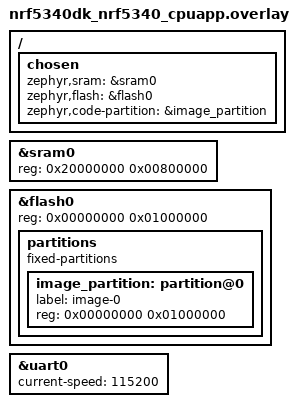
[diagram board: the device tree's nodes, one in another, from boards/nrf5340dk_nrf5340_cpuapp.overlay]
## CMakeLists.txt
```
#
# Copyright (c) 2021 Nordic Semiconductor
#
# SPDX-License-Identifier: LicenseRef-Nordic-5-Clause
#
cmake_minimum_required(VERSION 3.20)

find_package(Zephyr REQUIRED HINTS $ENV{ZEPHYR_BASE})
project(edge_ib C CXX)

# ---------------------------------------------------------
# 1. APPLICATION SOURCES
# ---------------------------------------------------------
target_sources(app PRIVATE
  src/main.cpp
  src/ML_Models/model_data.cc
  src/inference.cpp
  src/profiling.cpp
)

zephyr_library_include_directories(${CMAKE_CURRENT_SOURCE_DIR})
```

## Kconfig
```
# Options of this app. Set values in prj.conf, in a snippet or with -D<OPTION>=... at build time.

menu "Edge inference benchmark app"

config APP_TENSOR_ARENA_SIZE
	int "TFLM tensor arena size (bytes)"
	default 131072
	help
	  Static memory for all tensors of the inference (placed in RAM/.bss).
	  Default 128 KiB: fits the real nRF5340 DK (448 KiB RAM for the app).
	  The Renode variant sets more to test models of any size.
	  Actual need: see "Total Arena: used / size" in the UART log.

endmenu

# Must stay at the end: loads all Zephyr options (otherwise Kconfig only knows ours)
source "Kconfig.zephyr"
```

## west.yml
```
# West manifest for the nRF5340 firmware.
# Pins the SDK version and adds modules that NCS does not fetch by default.
#
#   west init -l <this directory>   &&   west update

manifest:
  version: "0.13"

  remotes:
    - name: ncs
      url-base: https://github.com/nrfconnect
    - name: zephyrproject
      url-base: https://github.com/zephyrproject-rtos

  projects:
    # nRF Connect SDK; import: true pulls in zephyr + all NCS modules
    - name: nrf
      remote: ncs
      repo-path: sdk-nrf
      revision: v2.6.0
      import: true

    # TFLite Micro is in Zephyr's "optional" submanifest, which NCS does not
    # import. Revision and path = as in Zephyr's optional.yaml for NCS v2.6.0
    # (the path ends up in __FILE__ strings, so it changes the binary).
    - name: tflite-micro
      remote: zephyrproject
      revision: 1a34dcab41e7e0e667db72d6a40999c1ec9c510c
      path: optional/modules/lib/tflite-micro
```

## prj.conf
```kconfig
#
# Copyright (c) 2021 Nordic Semiconductor ASA
#
# SPDX-License-Identifier: LicenseRef-Nordic-5-Clause
#

# Configuration shared by both variants (#1 Renode, #2 DK).
# Variant-specific settings live in snippets/<variant>/.

# Optimize for speed (we measure latency); size optimization would save flash instead
# CONFIG_SIZE_OPTIMIZATIONS=y
CONFIG_SPEED_OPTIMIZATIONS=y

# --- TensorFlow Lite Micro (C++17) with CMSIS-NN kernels ---
CONFIG_MAIN_STACK_SIZE=16384
CONFIG_CPP=y
CONFIG_NEWLIB_LIBC=y
CONFIG_LIB_CPLUSPLUS=y
CONFIG_STD_CPP17=y
CONFIG_TENSORFLOW_LITE_MICRO=y
CONFIG_TENSORFLOW_LITE_MICRO_CMSIS_NN_KERNELS=y

# --- Console output over UART (printk, floats for the RESULT line) ---
CONFIG_UART_CONSOLE=y
CONFIG_CONSOLE=y
CONFIG_SERIAL=y
CONFIG_LOG=y
CONFIG_PRINTK=y

CONFIG_CBPRINTF_FP_SUPPORT=y

# Synchronous logging/printk: no lost output when a lot is printed at once
CONFIG_LOG_MODE_IMMEDIATE=y
CONFIG_PRINTK_SYNC=y
CONFIG_LOG_BUFFER_SIZE=8192
```

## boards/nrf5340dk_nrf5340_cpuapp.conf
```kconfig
#
# Copyright (c) 2022 Nordic Semiconductor
#
# SPDX-License-Identifier: LicenseRef-Nordic-5-Clause
#

# Distance Measurement
CONFIG_DM_MODULE_RPC=y
CONFIG_DM_MODULE_RPC_CLIENT=y

CONFIG_TEST_RANDOM_GENERATOR=y
# CONFIG_ENTROPY_GENERATOR=y
# CONFIG_ENTROPY_DEVICE_RANDOM_GENERATOR=y
CONFIG_MPSL=n

# NRF RPC
CONFIG_NRF_RPC_THREAD_POOL_SIZE=2

# SYSTEM WORKQUEUE
CONFIG_SYSTEM_WORKQUEUE_STACK_SIZE=3072
```

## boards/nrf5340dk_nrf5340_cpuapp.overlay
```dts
// /*
//  * Copyright (c) 2022 Nordic Semiconductor ASA
//  *
//  * SPDX-License-Identifier: LicenseRef-Nordic-5-Clause
//  */

// #include <zephyr/dt-bindings/ipc_service/static_vrings.h>

// / {
// 	chosen {
// 		/delete-property/ zephyr,ipc_shm;
// 	};

// 	reserved-memory {
// 		/delete-node/ memory@20070000;

// 		sram_ipc0: memory@20070000 {
// 			reg = <0x20070000 0x8000>;
// 		};

// 		sram_ipc1: memory@20078000 {
// 			reg = <0x20078000 0x8000>;
// 		};
// 	};

// 	ipc {
// 		/delete-node/ ipc0;

// 		ipc0: ipc0 {
// 			compatible = "zephyr,ipc-openamp-static-vrings";
// 			memory-region = <&sram_ipc0>;
// 			mboxes = <&mbox 0>, <&mbox 1>;
// 			mbox-names = "tx", "rx";
// 			role = "host";
// 			status = "okay";
// 		};

// 		ipc1: ipc1 {
// 			compatible = "zephyr,ipc-openamp-static-vrings";
// 			memory-region = <&sram_ipc1>;
// 			mboxes = <&mbox 2>, <&mbox 3>;
// 			mbox-names = "tx", "rx";
// 			role = "host";
// 			zephyr,buffer-size = <2048>;
// 			status = "okay";
// 		};
// 	};
// };

//  /* Enable pin forwarding to network core. The selected pins will be used by
//   * Distance Measurement module for debug purposes.
//   *
//   * Note: Pay attention to assign the same GPIO pins as those provide in network core DTS overlay.
//   */
// &gpio_fwd {
// 	compatible = "nordic,nrf-gpio-forwarder";
// 	dm-gpio-if {
// 		gpios = <&gpio0 26 0>,
// 			<&gpio0 27 0>;
// 		};
// };

// &uart0 {
//     current-speed = <230400>;
//     status = "okay";
// };


/* boards/nrf5340dk_nrf5340_cpuapp.overlay */

/ {
	chosen {
		zephyr,sram = &sram0;
		zephyr,flash = &flash0;
		zephyr,code-partition = &image_partition;
	};
};

/* 1. RAM auf 8 MB erweitern */
&sram0 {
	reg = <0x20000000 0x00800000>; /* 8 MB virtueller SRAM */
};

/* 2. Flash auf 16 MB erweitern und Partitionierung anpassen */
&flash0 {
	reg = <0x00000000 0x01000000>; /* 16 MB virtueller Flash */

	partitions {
		compatible = "fixed-partitions";
		#address-cells = <1>;
		#size-cells = <1>;

		/* Voller Bereich als Binary-Image */
		image_partition: partition@0 {
			label = "image-0";
			reg = <0x00000000 0x01000000>;
		};
	};
};

/* UART für Ausgaben aktiv halten */
&uart0 {
	status = "okay";
	current-speed = <115200>;
};
```

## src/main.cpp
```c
#include <zephyr/kernel.h>
#include <zephyr/sys/printk.h>
#include "inference.hpp"
#include "data.hpp"
#include "ML_Models/model_data.h"

int main(void)
{
    printk("Starting Edge AI Benchmark on nRF5340...\n");

    if (!inference_init(g_model_data)) {
        printk("Initialization aborted.\n");
        return -1;
    }

    InferenceResult res;

    // First run (also records the per-layer profile)
    if (!inference_run(TEST_INPUT_SAMPLES[0], &res)) {
        printk("Inference failed.\n");
        return -1;
    }
    printk("[Warm-up Run] Pred: %6.3f | Latency: %u us | Cycles: %u\n",
           (double)res.prediction,
           res.execution_time_us,
           res.execution_cycles);

    // Print the detailed per-layer report
    inference_dump_profiling();

    // Machine-readable (JSON) for scripts/run_json.py, always the last line.
    // sha256 of the .tflite (embedded by codegen) -> the measurement is linked to the right model.
    printk("RESULT {\"model_sha256\": \"%s\", \"cycles\": %u, \"latency_us\": %u, "
           "\"arena_used_bytes\": %u, \"prediction\": %.4f}\n",
           g_model_data_sha256,
           res.execution_cycles,
           res.execution_time_us,
           static_cast<unsigned int>(inference_arena_used()),
           (double)res.prediction);

    return 0;
}
```

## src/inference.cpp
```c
#include "inference.hpp"
#include "profiling.hpp"

#include <zephyr/kernel.h>
#include <zephyr/sys/printk.h>
#include <string.h>
#include <math.h>

#include "tensorflow/lite/micro/recording_micro_interpreter.h"
#include "tensorflow/lite/micro/micro_mutable_op_resolver.h"
#include "tensorflow/lite/micro/system_setup.h"
#include "tensorflow/lite/schema/schema_generated.h"

// Size comes from Kconfig (CONFIG_APP_TENSOR_ARENA_SIZE) and differs per variant
#define TENSOR_ARENA_SIZE CONFIG_APP_TENSOR_ARENA_SIZE

alignas(16) static uint8_t tensor_arena[TENSOR_ARENA_SIZE];

static tflite::RecordingMicroInterpreter* interpreter = nullptr;
static const tflite::Model* current_model = nullptr;
static TfLiteTensor* input_tensor = nullptr;
static TfLiteTensor* output_tensor = nullptr;
static bool is_initialized = false;
static int total_input_elements = 0;

static DwtMicroProfiler profiler;

bool inference_init(const unsigned char* model_data)
{
    if (model_data == nullptr) {
        printk("Error: Model pointer is NULL\n");
        return false;
    }

    CoreDebug->DEMCR |= CoreDebug_DEMCR_TRCENA_Msk;
    DWT->CTRL |= DWT_CTRL_CYCCNTENA_Msk;
    DWT->CYCCNT = 0;

    tflite::InitializeTarget();

    current_model = tflite::GetModel(model_data);
    if (current_model->version() != TFLITE_SCHEMA_VERSION) {
        printk("Error: Model schema mismatch (Expected %d, got %d)\n",
               TFLITE_SCHEMA_VERSION, current_model->version());
        return false;
    }

    static tflite::MicroMutableOpResolver<30> resolver;
    resolver.AddFullyConnected();
    resolver.AddConv2D();
    resolver.AddDepthwiseConv2D();
    resolver.AddAveragePool2D();
    resolver.AddMaxPool2D();
    resolver.AddRelu();
    resolver.AddRelu6();
    resolver.AddHardSwish();
    resolver.AddSum();
    resolver.AddMean();
    resolver.AddAdd();
    resolver.AddMul();
    resolver.AddSub();
    resolver.AddLogistic();
    resolver.AddReshape();
    resolver.AddPad();
    resolver.AddQuantize();
    resolver.AddDequantize();
    resolver.AddSoftmax();

    static tflite::RecordingMicroInterpreter static_interpreter(
        current_model,
        resolver,
        tensor_arena,
        TENSOR_ARENA_SIZE,
        nullptr,
        &profiler
    );

    interpreter = &static_interpreter;

    if (interpreter->AllocateTensors() != kTfLiteOk) {
        printk("Error: AllocateTensors failed\n");
        return false;
    }

    input_tensor  = interpreter->input(0);
    output_tensor = interpreter->output(0);

    total_input_elements = 1;
    for (int i = 0; i < input_tensor->dims->size; ++i) {
        total_input_elements *= input_tensor->dims->data[i];
    }

    is_initialized = true;

    printk("TFLM initialized. Inputs: %d | Total Arena: %u / %d bytes\n",
           total_input_elements,
           static_cast<unsigned int>(interpreter->arena_used_bytes()), 
           TENSOR_ARENA_SIZE);

    printk("\n============================ MEMORY PROFILING REPORT ============================\n");
    interpreter->GetMicroAllocator().PrintAllocations();
    printk("==================================================================================\n\n");

    return true;
}

size_t inference_arena_used(void)
{
    return is_initialized ? interpreter->arena_used_bytes() : 0;
}

bool inference_run(const float* raw_features, InferenceResult* result)
{
    if (!is_initialized || raw_features == nullptr || result == nullptr) {
        return false;
    }

    if (input_tensor->type == kTfLiteFloat32) {
        memcpy(input_tensor->data.f, raw_features, sizeof(float) * total_input_elements);
    } 
    else if (input_tensor->type == kTfLiteInt8) {
        const float scale = input_tensor->params.scale;
        const int32_t zero_point = input_tensor->params.zero_point;

        for (int i = 0; i < total_input_elements; ++i) {
            int32_t q = static_cast<int32_t>(roundf(raw_features[i] / scale)) + zero_point;
            if (q < -128) q = -128;
            if (q > 127)  q = 127;
            input_tensor->data.int8[i] = static_cast<int8_t>(q);
        }
    } else {
        return false;
    }

    profiler.Reset();

    uint32_t start_cycles = DWT->CYCCNT;
    TfLiteStatus status = interpreter->Invoke();
    uint32_t stop_cycles = DWT->CYCCNT;
    uint32_t delta_cycles = stop_cycles - start_cycles;

    if (status != kTfLiteOk) {
        return false;
    }

    float predicted_value = 0.0f;
    if (output_tensor->type == kTfLiteFloat32) {
        predicted_value = output_tensor->data.f[0];
    } else if (output_tensor->type == kTfLiteInt8) {
        const float scale = output_tensor->params.scale;
        const int32_t zero_point = output_tensor->params.zero_point;
        predicted_value = (static_cast<float>(output_tensor->data.int8[0]) - zero_point) * scale;
    }

    result->prediction = predicted_value;
    result->execution_cycles = delta_cycles;
    result->execution_time_us = delta_cycles / 128;

    return true;
}

void inference_dump_profiling(void)
{
    if (current_model && interpreter) {
        profiler.PrintSummary(current_model, 128);

        printk("\n============================ MEMORY PROFILING REPORT ============================\n");
        interpreter->GetMicroAllocator().PrintAllocations();
        printk("==================================================================================\n\n");
    }
}
```

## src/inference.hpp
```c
#pragma once

#include <stddef.h>
#include <stdint.h>
#include <stdbool.h>

#ifdef __cplusplus
extern "C" {
#endif

typedef struct {
    float prediction;
    uint32_t execution_cycles;
    uint32_t execution_time_us;
} InferenceResult;

bool inference_init(const unsigned char* model_data);
bool inference_run(const float* raw_features, InferenceResult* result);
void inference_dump_profiling(void);
size_t inference_arena_used(void);

#ifdef __cplusplus
}
#endif
```

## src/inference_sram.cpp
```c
#include "inference.hpp"
#include "profiling.hpp"

#include <zephyr/kernel.h>
#include <zephyr/sys/printk.h>
#include <string.h>
#include <math.h>

#include "tensorflow/lite/micro/recording_micro_interpreter.h"
#include "tensorflow/lite/micro/micro_mutable_op_resolver.h"
#include "tensorflow/lite/micro/system_setup.h"
#include "tensorflow/lite/schema/schema_generated.h"

// 2 MB buffer for the MobileNet flatbuffer mirrored into SRAM
#define MODEL_SRAM_BUFFER_SIZE (3 * 1024 * 1024)
alignas(16) static uint8_t s_model_sram[MODEL_SRAM_BUFFER_SIZE];

// 3 MB tensor arena for activations, intermediate tensors and scratch buffers
// Size comes from Kconfig (CONFIG_APP_TENSOR_ARENA_SIZE) and differs per variant
#define TENSOR_ARENA_SIZE CONFIG_APP_TENSOR_ARENA_SIZE
alignas(16) static uint8_t tensor_arena[TENSOR_ARENA_SIZE];

static tflite::RecordingMicroInterpreter* interpreter = nullptr;
static const tflite::Model* current_model = nullptr;
static TfLiteTensor* input_tensor = nullptr;
static TfLiteTensor* output_tensor = nullptr;
static bool is_initialized = false;
static int total_input_elements = 0;

static DwtMicroProfiler profiler;

// Size of the generated model from model_data.h/cc
extern const size_t g_model_data_len;

bool inference_init(const unsigned char* model_data)
{
    if (model_data == nullptr) {
        printk("Error: Model pointer is NULL\n");
        return false;
    }

    // Enable the DWT cycle counter
    CoreDebug->DEMCR |= CoreDebug_DEMCR_TRCENA_Msk;
    DWT->CTRL |= DWT_CTRL_CYCCNTENA_Msk;
    DWT->CYCCNT = 0;

    tflite::InitializeTarget();

    // 1. Check the model size and mirror the whole model into SRAM
    if (g_model_data_len > MODEL_SRAM_BUFFER_SIZE) {
        printk("Error: Model size (%u bytes) exceeds SRAM buffer (%u bytes)!\n",
               (unsigned int)g_model_data_len, MODEL_SRAM_BUFFER_SIZE);
        return false;
    }

    memcpy(s_model_sram, model_data, g_model_data_len);

    printk("[SRAM Mirror] Model mirrored to SRAM at: 0x%08X (%u bytes)\n",
           (uintptr_t)s_model_sram, (unsigned int)g_model_data_len);

    // 2. GetModel uses the SRAM buffer directly (weights are now read from SRAM)
    current_model = tflite::GetModel(s_model_sram);
    if (current_model->version() != TFLITE_SCHEMA_VERSION) {
        printk("Error: Model schema mismatch (Expected %d, got %d)\n",
               TFLITE_SCHEMA_VERSION, current_model->version());
        return false;
    }

    // 3. Op resolver with room for 30 ops
    static tflite::MicroMutableOpResolver<30> resolver;
    resolver.AddFullyConnected();
    resolver.AddConv2D();
    resolver.AddDepthwiseConv2D();
    resolver.AddAveragePool2D();
    resolver.AddMaxPool2D();
    resolver.AddRelu();
    resolver.AddRelu6();
    resolver.AddHardSwish();
    resolver.AddSum();
    resolver.AddMean();
    resolver.AddAdd();
    resolver.AddMul();
    resolver.AddSub();
    resolver.AddLogistic();
    resolver.AddReshape();
    resolver.AddPad();
    resolver.AddTranspose();
    resolver.AddQuantize();
    resolver.AddDequantize();
    resolver.AddSoftmax();

    static tflite::RecordingMicroInterpreter static_interpreter(
        current_model,
        resolver,
        tensor_arena,
        TENSOR_ARENA_SIZE,
        nullptr,
        &profiler
    );

    interpreter = &static_interpreter;

    if (interpreter->AllocateTensors() != kTfLiteOk) {
        printk("Error: AllocateTensors failed\n");
        return false;
    }

    input_tensor  = interpreter->input(0);
    output_tensor = interpreter->output(0);

    total_input_elements = 1;
    for (int i = 0; i < input_tensor->dims->size; ++i) {
        total_input_elements *= input_tensor->dims->data[i];
    }

    is_initialized = true;

    printk("TFLM initialized. Inputs: %d | Total Arena: %u / %d bytes\n",
           total_input_elements,
           static_cast<unsigned int>(interpreter->arena_used_bytes()), 
           TENSOR_ARENA_SIZE);

    printk("\n============================ MEMORY PROFILING REPORT ============================\n");
    interpreter->GetMicroAllocator().PrintAllocations();
    printk("==================================================================================\n\n");

    return true;
}

bool inference_run(const float* raw_features, InferenceResult* result)
{
    if (!is_initialized || raw_features == nullptr || result == nullptr) {
        return false;
    }

    if (input_tensor->type == kTfLiteFloat32) {
        memcpy(input_tensor->data.f, raw_features, sizeof(float) * total_input_elements);
    } 
    else if (input_tensor->type == kTfLiteInt8) {
        const float scale = input_tensor->params.scale;
        const int32_t zero_point = input_tensor->params.zero_point;

        for (int i = 0; i < total_input_elements; ++i) {
            int32_t q = static_cast<int32_t>(roundf(raw_features[i] / scale)) + zero_point;
            if (q < -128) q = -128;
            if (q > 127)  q = 127;
            input_tensor->data.int8[i] = static_cast<int8_t>(q);
        }
    } else {
        return false;
    }

    profiler.Reset();

    uint32_t start_cycles = DWT->CYCCNT;
    TfLiteStatus status = interpreter->Invoke();
    uint32_t stop_cycles = DWT->CYCCNT;
    uint32_t delta_cycles = stop_cycles - start_cycles;

    if (status != kTfLiteOk) {
        return false;
    }

    float predicted_value = 0.0f;
    if (output_tensor->type == kTfLiteFloat32) {
        predicted_value = output_tensor->data.f[0];
    } else if (output_tensor->type == kTfLiteInt8) {
        const float scale = output_tensor->params.scale;
        const int32_t zero_point = output_tensor->params.zero_point;
        predicted_value = (static_cast<float>(output_tensor->data.int8[0]) - zero_point) * scale;
    }

    result->prediction = predicted_value;
    result->execution_cycles = delta_cycles;
    result->execution_time_us = delta_cycles / 128;

    return true;
}

void inference_dump_profiling(void)
{
    if (current_model && interpreter) {
        profiler.PrintSummary(current_model, 128);

        printk("\n============================ MEMORY PROFILING REPORT ============================\n");
        interpreter->GetMicroAllocator().PrintAllocations();
        printk("==================================================================================\n\n");
    }
}
```

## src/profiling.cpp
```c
#include "profiling.hpp"
#include <zephyr/sys/printk.h>
#include <zephyr/kernel.h>
#include <string.h>

DwtMicroProfiler::DwtMicroProfiler() : num_events_(0) {
    memset(events_, 0, sizeof(events_));
}

void DwtMicroProfiler::InitHardware() {
    CoreDebug->DEMCR |= CoreDebug_DEMCR_TRCENA_Msk;

    uint32_t ctrl_mask = DWT_CTRL_CYCCNTENA_Msk;
#if defined(DWT_CTRL_LSUEVTENA_Msk)
    ctrl_mask |= DWT_CTRL_LSUEVTENA_Msk;
#elif defined(DWT_CTRL_LSUCNTENA_Msk)
    ctrl_mask |= DWT_CTRL_LSUCNTENA_Msk;
#endif

#if defined(DWT_CTRL_CPIEVTENA_Msk)
    ctrl_mask |= DWT_CTRL_CPIEVTENA_Msk;
#elif defined(DWT_CTRL_CPICNTENA_Msk)
    ctrl_mask |= DWT_CTRL_CPICNTENA_Msk;
#endif

    DWT->CTRL |= ctrl_mask;
    DWT->CYCCNT = 0;
    DWT->LSUCNT = 0;
    DWT->CPICNT = 0;

    printk("[Profiler] Cortex-M33 DWT Memory & Stall Profiler: ACTIVE\n");
}

void DwtMicroProfiler::Reset() {
    num_events_ = 0;
    DWT->LSUCNT = 0;
    DWT->CPICNT = 0;
}

uint32_t DwtMicroProfiler::BeginEvent(const char* tag) {
    if (num_events_ >= PROFILER_MAX_EVENTS) {
        return 0xFFFFFFFF;
    }
    uint32_t handle = num_events_++;
    events_[handle].tag = tag;
    events_[handle].start_lsu    = DWT->LSUCNT;
    events_[handle].start_cpi    = DWT->CPICNT;
    events_[handle].start_cycles = DWT->CYCCNT;
    return handle;
}

void DwtMicroProfiler::EndEvent(uint32_t event_handle) {
    uint32_t stop_cycles = DWT->CYCCNT;
    uint32_t stop_lsu    = DWT->LSUCNT;
    uint32_t stop_cpi    = DWT->CPICNT;

    if (event_handle != 0xFFFFFFFF && event_handle < num_events_) {
        events_[event_handle].total_cycles = stop_cycles - events_[event_handle].start_cycles;
        events_[event_handle].total_lsu    = (stop_lsu - events_[event_handle].start_lsu) & 0xFF;
        events_[event_handle].total_cpi    = (stop_cpi - events_[event_handle].start_cpi) & 0xFF;
    }
}

uint64_t DwtMicroProfiler::CalculateOperatorMacs(const tflite::Operator* op, 
                                               const tflite::SubGraph* subgraph, 
                                               tflite::BuiltinOperator op_type) {
    if (!op || !subgraph) return 0;

    auto inputs  = op->inputs();
    auto outputs = op->outputs();
    auto tensors = subgraph->tensors();

    if (!inputs || !outputs || !tensors) return 0;
    if (inputs->size() < 2 || outputs->size() < 1) return 0;

    int32_t weight_idx = inputs->Get(1);
    int32_t output_idx = outputs->Get(0);

    if (weight_idx < 0 || weight_idx >= static_cast<int32_t>(tensors->size())) return 0;
    if (output_idx < 0 || output_idx >= static_cast<int32_t>(tensors->size())) return 0;

    const tflite::Tensor* weight_tensor = tensors->Get(weight_idx);
    const tflite::Tensor* output_tensor = tensors->Get(output_idx);

    if (!weight_tensor || !output_tensor || !weight_tensor->shape() || !output_tensor->shape()) {
        return 0;
    }

    auto w_shape = weight_tensor->shape();
    auto o_shape = output_tensor->shape();

    // 1. Fully Connected (Weight: [out_features, in_features])
    if (op_type == tflite::BuiltinOperator_FULLY_CONNECTED && w_shape->size() == 2) {
        return static_cast<uint64_t>(w_shape->Get(0)) * static_cast<uint64_t>(w_shape->Get(1));
    }

    // 2. Convolutions (4D Shapes)
    if (w_shape->size() == 4 && o_shape->size() == 4) {
        uint64_t h_out = static_cast<uint64_t>(o_shape->Get(1));
        uint64_t w_out = static_cast<uint64_t>(o_shape->Get(2));
        uint64_t c_out = static_cast<uint64_t>(o_shape->Get(3));

        uint64_t k_h = static_cast<uint64_t>(w_shape->Get(1));
        uint64_t k_w = static_cast<uint64_t>(w_shape->Get(2));

        if (op_type == tflite::BuiltinOperator_DEPTHWISE_CONV_2D) {
            // Depthwise: each output channel multiplies exactly one kernel patch (no C_in factor)
            return h_out * w_out * c_out * (k_h * k_w);
        } 
        else if (op_type == tflite::BuiltinOperator_CONV_2D) {
            // Standard Conv2D: filter shape is [C_out, K_H, K_W, C_in]
            uint64_t c_in = static_cast<uint64_t>(w_shape->Get(3));
            return h_out * w_out * c_out * (k_h * k_w * c_in);
        }
    }

    return 0;
}

void DwtMicroProfiler::PrintSummary(const tflite::Model* model, uint32_t cpu_freq_mhz) {
    if (num_events_ == 0) {
        printk("[Profiler] No layer events recorded.\n");
        return;
    }

    uint64_t total_model_cycles = 0;
    for (uint32_t i = 0; i < num_events_; ++i) {
        total_model_cycles += events_[i].total_cycles;
    }

    auto subgraphs = model->subgraphs();
    const tflite::SubGraph* subgraph = subgraphs ? subgraphs->Get(0) : nullptr;
    auto operators = subgraph ? subgraph->operators() : nullptr;
    auto opcodes = model->operator_codes();

    printk("\n=================================== ADVANCED HARDWARE PROFILING REPORT ===================================\n");
    printk("%-3s | %-20s | %-9s | %-8s | %-7s | %-9s | %-8s | %-15s\n", 
           "Idx", "Operator Type", "Cycles", "Time(us)", "% Total", "Cyc/MAC", "LSU-Wait", "Classification");
    printk("----------------------------------------------------------------------------------------------------------\n");

    for (uint32_t i = 0; i < num_events_; ++i) {
        const char* op_name = "UnknownOp";
        uint64_t macs = 0;
        tflite::BuiltinOperator builtin_code = tflite::BuiltinOperator_CUSTOM;

        if (operators && opcodes && i < operators->size()) {
            const tflite::Operator* op = operators->Get(i);
            uint32_t opcode_index = op->opcode_index();
            if (opcode_index < opcodes->size()) {
                const tflite::OperatorCode* op_code = opcodes->Get(opcode_index);
                builtin_code = op_code->builtin_code();
                if (builtin_code == tflite::BuiltinOperator_PLACEHOLDER_FOR_GREATER_OP_CODES) {
                    builtin_code = static_cast<tflite::BuiltinOperator>(op_code->deprecated_builtin_code());
                }
                op_name = tflite::EnumNameBuiltinOperator(builtin_code);
            }
            macs = CalculateOperatorMacs(op, subgraph, builtin_code);
        }

        uint32_t time_us = events_[i].total_cycles / cpu_freq_mhz;
        uint32_t percent_x10 = (total_model_cycles > 0) 
            ? static_cast<uint32_t>((static_cast<uint64_t>(events_[i].total_cycles) * 1000ULL) / total_model_cycles) 
            : 0;

        float cyc_per_mac = 0.0f;
        const char* bound_desc = "OTHER";

        if (macs > 0) {
            cyc_per_mac = static_cast<float>(events_[i].total_cycles) / static_cast<float>(macs);

            if (cyc_per_mac < 1.25f) {
                bound_desc = "COMPUTE";
            } else if (cyc_per_mac < 2.5f) {
                bound_desc = "BALANCED";
            } else {
                bound_desc = "MEMORY_FLASH";
            }
        } else {
            if (builtin_code == tflite::BuiltinOperator_ADD || 
                builtin_code == tflite::BuiltinOperator_MUL || 
                builtin_code == tflite::BuiltinOperator_SUM ||
                builtin_code == tflite::BuiltinOperator_HARD_SWISH) {
                bound_desc = "ELEMENTWISE_RAM";
            } else if (builtin_code == tflite::BuiltinOperator_PAD || 
                       builtin_code == tflite::BuiltinOperator_TRANSPOSE ||
                       builtin_code == tflite::BuiltinOperator_RESHAPE) {
                bound_desc = "IO_OVERHEAD";
            }
        }

        if (macs > 0) {
            printk("%-3u | %-20s | %-9u | %-8u | %3u.%1u%% | %7.2f   | %-8u | %-15s\n",
                   i, op_name, events_[i].total_cycles, time_us,
                   percent_x10 / 10, percent_x10 % 10,
                   static_cast<double>(cyc_per_mac),
                   events_[i].total_lsu,
                   bound_desc);
        } else {
            printk("%-3u | %-20s | %-9u | %-8u | %3u.%1u%% |    --     | %-8u | %-15s\n",
                   i, op_name, events_[i].total_cycles, time_us,
                   percent_x10 / 10, percent_x10 % 10,
                   events_[i].total_lsu,
                   bound_desc);
        }
    }

    uint32_t total_time_us = static_cast<uint32_t>(total_model_cycles / cpu_freq_mhz);
    printk("----------------------------------------------------------------------------------------------------------\n");
    printk("Total Layer Time: %u us (%u ms) | Total Cycles: %llu\n", 
           total_time_us, 
           total_time_us / 1000, 
           total_model_cycles);
    printk("Classification Legend:\n");
    printk("  COMPUTE         : Cyc/MAC < 1.25 -> DSP SMLAD pipeline fully utilized\n");
    printk("  BALANCED        : 1.25 <= Cyc/MAC < 2.5 -> compute and load pipelines balanced\n");
    printk("  MEMORY_FLASH    : Cyc/MAC >= 2.5 -> flash bus wait states / D-code latency dominate\n");
    printk("  ELEMENTWISE_RAM : no MACs -> element-wise byte loads/stores load the SRAM\n");
    printk("  IO_OVERHEAD     : memory copies (padding / reshape / transpose)\n");
    printk("==========================================================================================================\n\n");
}
```

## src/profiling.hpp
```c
#pragma once

#include <stdint.h>
#include <stddef.h>
#include "tensorflow/lite/micro/micro_profiler_interface.h"
#include "tensorflow/lite/schema/schema_generated.h"

#define PROFILER_MAX_EVENTS 512

struct LayerProfile {
    const char* tag;
    uint32_t start_cycles;
    uint32_t total_cycles;
    uint32_t start_lsu;
    uint32_t total_lsu;
    uint32_t start_cpi;
    uint32_t total_cpi;
};

class DwtMicroProfiler : public tflite::MicroProfilerInterface {
public:
    DwtMicroProfiler();

    // Hardware init of the Cortex-M33 DWT registers
    void InitHardware();

    // TFLM Profiler Interface
    uint32_t BeginEvent(const char* tag) override;
    void EndEvent(uint32_t event_handle) override;

    // Analysis and report
    void Reset();
    void PrintSummary(const tflite::Model* model, uint32_t cpu_freq_mhz = 128);

private:
    LayerProfile events_[PROFILER_MAX_EVENTS];
    uint32_t num_events_;

    // Computes the theoretical MACs from the flatbuffer tensor shapes
    uint64_t CalculateOperatorMacs(const tflite::Operator* op, 
                                   const tflite::SubGraph* subgraph, 
                                   tflite::BuiltinOperator op_type);
};
```

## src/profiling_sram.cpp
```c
#include "profiling.hpp"
#include <zephyr/sys/printk.h>
#include <zephyr/kernel.h>
#include <string.h>

DwtMicroProfiler::DwtMicroProfiler() : num_events_(0) {
    memset(events_, 0, sizeof(events_));
}

void DwtMicroProfiler::Reset() {
    num_events_ = 0;
}

uint32_t DwtMicroProfiler::BeginEvent(const char* tag) {
    if (num_events_ >= PROFILER_MAX_EVENTS) {
        return 0xFFFFFFFF; // Invalid handle, so that event 0 is never overwritten
    }
    uint32_t handle = num_events_++;
    events_[handle].tag = tag;
    events_[handle].start_cycles = DWT->CYCCNT;
    return handle;
}

void DwtMicroProfiler::EndEvent(uint32_t event_handle) {
    uint32_t stop_cycles = DWT->CYCCNT;
    if (event_handle != 0xFFFFFFFF && event_handle < num_events_) {
        events_[event_handle].total_cycles = stop_cycles - events_[event_handle].start_cycles;
    }
}

void DwtMicroProfiler::PrintSummary(const tflite::Model* model, uint32_t cpu_freq_mhz) {
    if (num_events_ == 0) {
        printk("[Profiler] No layer events recorded.\n");
        return;
    }

    uint64_t total_model_cycles = 0;
    for (uint32_t i = 0; i < num_events_; ++i) {
        total_model_cycles += events_[i].total_cycles;
    }

    auto subgraphs = model->subgraphs();
    const tflite::SubGraph* subgraph = subgraphs ? subgraphs->Get(0) : nullptr;
    auto operators = subgraph ? subgraph->operators() : nullptr;
    auto opcodes = model->operator_codes();

    printk("\n============================= LAYER PROFILING REPORT (SRAM EXECUTION) =============================\n");
    printk("%-4s | %-24s | %-12s | %-10s | %-7s\n", "Idx", "Operator Type", "Cycles", "Time (us)", "% Total");
    printk("----------------------------------------------------------------------------------------------------\n");

    for (uint32_t i = 0; i < num_events_; ++i) {
        const char* op_name = "UnknownOp";

        if (operators && opcodes && i < operators->size()) {
            const tflite::Operator* op = operators->Get(i);
            uint32_t opcode_index = op->opcode_index();
            if (opcode_index < opcodes->size()) {
                const tflite::OperatorCode* op_code = opcodes->Get(opcode_index);
                tflite::BuiltinOperator builtin_code = op_code->builtin_code();
                if (builtin_code == tflite::BuiltinOperator_PLACEHOLDER_FOR_GREATER_OP_CODES) {
                    builtin_code = static_cast<tflite::BuiltinOperator>(op_code->deprecated_builtin_code());
                }
                op_name = tflite::EnumNameBuiltinOperator(builtin_code);
            }
        }

        uint32_t time_us = events_[i].total_cycles / cpu_freq_mhz;

        // Percentage computed in uint64_t to avoid overflow
        uint32_t percent_x10 = (total_model_cycles > 0) 
            ? static_cast<uint32_t>((static_cast<uint64_t>(events_[i].total_cycles) * 1000ULL) / total_model_cycles) 
            : 0;

        printk("%-4u | %-24s | %-12u | %-10u | %3u.%1u%%\n",
               i,
               op_name,
               events_[i].total_cycles,
               time_us,
               percent_x10 / 10,
               percent_x10 % 10);
    }

    uint32_t total_time_us = static_cast<uint32_t>(total_model_cycles / cpu_freq_mhz);
    printk("----------------------------------------------------------------------------------------------------\n");
    printk("Total Layer Time: %u us (%u ms) | Total Cycles: %llu\n", 
           total_time_us, 
           total_time_us / 1000, 
           total_model_cycles);
    printk("====================================================================================================\n\n");
}
```

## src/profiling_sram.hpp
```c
#pragma once

#include <stdint.h>
#include <stddef.h>
#include "tensorflow/lite/micro/micro_profiler_interface.h"
#include "tensorflow/lite/schema/schema_generated.h"

#define PROFILER_MAX_EVENTS 512

struct LayerProfile {
    const char* tag;
    uint32_t start_cycles;
    uint32_t total_cycles;
};

class DwtMicroProfiler : public tflite::MicroProfilerInterface {
public:
    DwtMicroProfiler();

    // TFLM Profiler Interface
    uint32_t BeginEvent(const char* tag) override;
    void EndEvent(uint32_t event_handle) override;

    // Analysis and report
    void Reset();
    void PrintSummary(const tflite::Model* model, uint32_t cpu_freq_mhz = 128);

private:
    LayerProfile events_[PROFILER_MAX_EVENTS];
    uint32_t num_events_;
};
```
